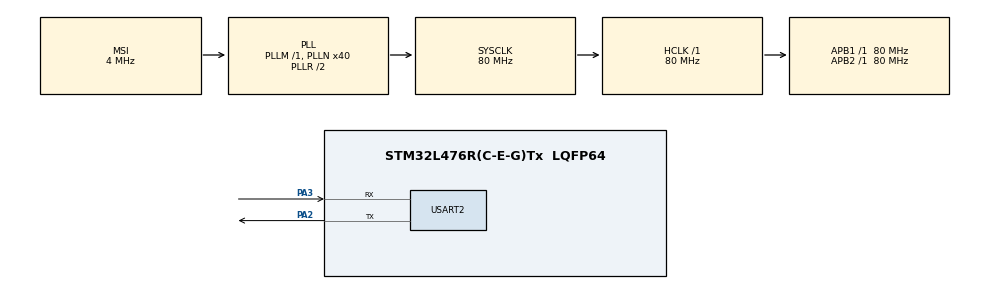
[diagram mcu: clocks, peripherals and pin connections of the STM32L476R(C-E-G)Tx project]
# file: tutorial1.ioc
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ADC1.Channel-5\#ChannelRegularConversion=ADC_CHANNEL_TEMPSENSOR
ADC1.NbrOfConversionFlag=1
ADC1.OffsetNumber-5\#ChannelRegularConversion=ADC_OFFSET_NONE
ADC1.Rank-5\#ChannelRegularConversion=1
ADC1.SamplingTime-5\#ChannelRegularConversion=ADC_SAMPLETIME_2CYCLES_5
ADC1.master=1
Mcu.Family=STM32L4
Mcu.Name=STM32L476R(C-E-G)Tx
Mcu.Package=LQFP64
NVIC.PriorityGroup=NVIC_PRIORITYGROUP_4
PA2.Mode=Asynchronous
PA2.Signal=USART2_TX
PA3.Mode=Asynchronous
PA3.Signal=USART2_RX
PH0-OSC_IN\ (PH0).Mode=HSE-External-Oscillator
PH0-OSC_IN\ (PH0).Signal=RCC_OSC_IN
PH1-OSC_OUT\ (PH1).Mode=HSE-External-Oscillator
PH1-OSC_OUT\ (PH1).Signal=RCC_OSC_OUT
ProjectManager.HeapSize=0x200
ProjectManager.StackSize=0x400
ProjectManager.TargetToolchain=MDK-ARM V5
RCC.ADCFreq_Value=48000000
RCC.AHBFreq_Value=80000000
RCC.APB1Freq_Value=80000000
RCC.APB1TimFreq_Value=80000000
RCC.APB2Freq_Value=80000000
RCC.APB2TimFreq_Value=80000000
RCC.CortexFreq_Value=80000000
RCC.HCLKFreq_Value=80000000
RCC.HSE_VALUE=8000000
RCC.HSI_VALUE=16000000
RCC.LSE_VALUE=32768
RCC.MSI_VALUE=4000000
RCC.PLLN=40
RCC.PLLSAI1N=24
RCC.SYSCLKFreq_VALUE=80000000
RCC.SYSCLKSource=RCC_SYSCLKSOURCE_PLLCLK
RCC.USBFreq_Value=48000000
RCC.VCOOutputFreq_Value=160000000
USART2.VirtualMode-Asynchronous=VM_ASYNC
VP_ADC1_TempSens_Input.Mode=IN-TempSens
board=custom

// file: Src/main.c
/* USER CODE BEGIN Header */
/**
  ******************************************************************************
  * @file           : main.c
  * @brief          : Main program body
  ******************************************************************************
  ** This notice applies to any and all portions of this file
  * that are not between comment pairs USER CODE BEGIN and
  * USER CODE END. Other portions of this file, whether
  * inserted by the user or by software development tools
  * are owned by their respective copyright owners.
  *
  * COPYRIGHT(c) 2019 STMicroelectronics
  *
  * Redistribution and use in source and binary forms, with or without modification,
  * are permitted provided that the following conditions are met:
  *   1. Redistributions of source code must retain the above copyright notice,
  *      this list of conditions and the following disclaimer.
  *   2. Redistributions in binary form must reproduce the above copyright notice,
  *      this list of conditions and the following disclaimer in the documentation
  *      and/or other materials provided with the distribution.
  *   3. Neither the name of STMicroelectronics nor the names of its contributors
  *      may be used to endorse or promote products derived from this software
  *      without specific prior written permission.
  *
  * THIS SOFTWARE IS PROVIDED BY THE COPYRIGHT HOLDERS AND CONTRIBUTORS "AS IS"
  * AND ANY EXPRESS OR IMPLIED WARRANTIES, INCLUDING, BUT NOT LIMITED TO, THE
  * IMPLIED WARRANTIES OF MERCHANTABILITY AND FITNESS FOR A PARTICULAR PURPOSE ARE
  * DISCLAIMED. IN NO EVENT SHALL THE COPYRIGHT HOLDER OR CONTRIBUTORS BE LIABLE
  * FOR ANY DIRECT, INDIRECT, INCIDENTAL, SPECIAL, EXEMPLARY, OR CONSEQUENTIAL
  * DAMAGES (INCLUDING, BUT NOT LIMITED TO, PROCUREMENT OF SUBSTITUTE GOODS OR
  * SERVICES; LOSS OF USE, DATA, OR PROFITS; OR BUSINESS INTERRUPTION) HOWEVER
  * CAUSED AND ON ANY THEORY OF LIABILITY, WHETHER IN CONTRACT, STRICT LIABILITY,
  * OR TORT (INCLUDING NEGLIGENCE OR OTHERWISE) ARISING IN ANY WAY OUT OF THE USE
  * OF THIS SOFTWARE, EVEN IF ADVISED OF THE POSSIBILITY OF SUCH DAMAGE.
  *
  ******************************************************************************
  */
/* USER CODE END Header */

#include "main.h"

ADC_HandleTypeDef hadc1;

UART_HandleTypeDef huart2;

void SystemClock_Config(void);
static void MX_GPIO_Init(void);
static void MX_ADC1_Init(void);
static void MX_USART2_UART_Init(void);

int main(void)
{

  /* MCU Configuration--------------------------------------------------------*/

  /* Reset of all peripherals, Initializes the Flash interface and the Systick. */
  HAL_Init();

  /* Configure the system clock */
  SystemClock_Config();

  /* Initialize all configured peripherals */
  MX_GPIO_Init();
  MX_ADC1_Init();
  MX_USART2_UART_Init();

  /* Infinite loop */
  /* USER CODE BEGIN WHILE */
	uint8_t dataIn[2]={'9','9'};
	uint8_t data[11]={'M','E','S','S','U','R','E',' ','I','S',' '};
	uint8_t tab[3]={' ',' ',' '};
	uint8_t messureADC=53;
	uint8_t messureADC2=53;
	uint8_t Vsense=53;
  while (1)
  {
    /* USER CODE END WHILE */

    /* USER CODE BEGIN 3 */
		HAL_ADC_Start(&hadc1);
		if(HAL_ADC_PollForConversion(&hadc1,2000)==HAL_OK){
		messureADC=HAL_ADC_GetValue(&hadc1);
		Vsense=(3*messureADC/4095);
		messureADC = ((Vsense-0.76)/0.0025)+25;
			dataIn[0]=(messureADC/10)+'0';
			dataIn[1]=(messureADC%10)+'0';

		}
		//HAL_UART_Receive(&huart1,data,11,1000);
		HAL_UART_Transmit(&huart2,data,11,1000);
		HAL_UART_Transmit(&huart2,dataIn,2,1000);
		HAL_UART_Transmit(&huart2,tab,3,1000);
		HAL_Delay(3000);
		//Debuggers is saying the temperature value is 23 i have to convert it to the ascii code

  }
  /* USER CODE END 3 */
}

void SystemClock_Config(void)
{
  RCC_OscInitTypeDef RCC_OscInitStruct = {0};
  RCC_ClkInitTypeDef RCC_ClkInitStruct = {0};
  RCC_PeriphCLKInitTypeDef PeriphClkInit = {0};

  /**Initializes the CPU, AHB and APB busses clocks
  */
  RCC_OscInitStruct.OscillatorType = RCC_OSCILLATORTYPE_MSI;
  RCC_OscInitStruct.MSIState = RCC_MSI_ON;
  RCC_OscInitStruct.MSICalibrationValue = 0;
  RCC_OscInitStruct.MSIClockRange = RCC_MSIRANGE_6;
  RCC_OscInitStruct.PLL.PLLState = RCC_PLL_ON;
  RCC_OscInitStruct.PLL.PLLSource = RCC_PLLSOURCE_MSI;
  RCC_OscInitStruct.PLL.PLLM = 1;
  RCC_OscInitStruct.PLL.PLLN = 40;
  RCC_OscInitStruct.PLL.PLLP = RCC_PLLP_DIV7;
  RCC_OscInitStruct.PLL.PLLQ = RCC_PLLQ_DIV2;
  RCC_OscInitStruct.PLL.PLLR = RCC_PLLR_DIV2;
  if (HAL_RCC_OscConfig(&RCC_OscInitStruct) != HAL_OK)
  {
    Error_Handler();
  }
  /**Initializes the CPU, AHB and APB busses clocks
  */
  RCC_ClkInitStruct.ClockType = RCC_CLOCKTYPE_HCLK|RCC_CLOCKTYPE_SYSCLK
                              |RCC_CLOCKTYPE_PCLK1|RCC_CLOCKTYPE_PCLK2;
  RCC_ClkInitStruct.SYSCLKSource = RCC_SYSCLKSOURCE_PLLCLK;
  RCC_ClkInitStruct.AHBCLKDivider = RCC_SYSCLK_DIV1;
  RCC_ClkInitStruct.APB1CLKDivider = RCC_HCLK_DIV1;
  RCC_ClkInitStruct.APB2CLKDivider = RCC_HCLK_DIV1;

  if (HAL_RCC_ClockConfig(&RCC_ClkInitStruct, FLASH_LATENCY_4) != HAL_OK)
  {
    Error_Handler();
  }
  PeriphClkInit.PeriphClockSelection = RCC_PERIPHCLK_USART2|RCC_PERIPHCLK_ADC;
  PeriphClkInit.Usart2ClockSelection = RCC_USART2CLKSOURCE_PCLK1;
  PeriphClkInit.AdcClockSelection = RCC_ADCCLKSOURCE_PLLSAI1;
  PeriphClkInit.PLLSAI1.PLLSAI1Source = RCC_PLLSOURCE_MSI;
  PeriphClkInit.PLLSAI1.PLLSAI1M = 1;
  PeriphClkInit.PLLSAI1.PLLSAI1N = 24;
  PeriphClkInit.PLLSAI1.PLLSAI1P = RCC_PLLP_DIV7;
  PeriphClkInit.PLLSAI1.PLLSAI1Q = RCC_PLLQ_DIV2;
  PeriphClkInit.PLLSAI1.PLLSAI1R = RCC_PLLR_DIV2;
  PeriphClkInit.PLLSAI1.PLLSAI1ClockOut = RCC_PLLSAI1_ADC1CLK;
  if (HAL_RCCEx_PeriphCLKConfig(&PeriphClkInit) != HAL_OK)
  {
    Error_Handler();
  }
  /**Configure the main internal regulator output voltage
  */
  if (HAL_PWREx_ControlVoltageScaling(PWR_REGULATOR_VOLTAGE_SCALE1) != HAL_OK)
  {
    Error_Handler();
  }
}

static void MX_ADC1_Init(void)
{

  ADC_MultiModeTypeDef multimode = {0};
  ADC_ChannelConfTypeDef sConfig = {0};

  /**Common config
  */
  hadc1.Instance = ADC1;
  hadc1.Init.ClockPrescaler = ADC_CLOCK_ASYNC_DIV1;
  hadc1.Init.Resolution = ADC_RESOLUTION_12B;
  hadc1.Init.DataAlign = ADC_DATAALIGN_RIGHT;
  hadc1.Init.ScanConvMode = ADC_SCAN_DISABLE;
  hadc1.Init.EOCSelection = ADC_EOC_SINGLE_CONV;
  hadc1.Init.LowPowerAutoWait = DISABLE;
  hadc1.Init.ContinuousConvMode = DISABLE;
  hadc1.Init.NbrOfConversion = 1;
  hadc1.Init.DiscontinuousConvMode = DISABLE;
  hadc1.Init.ExternalTrigConv = ADC_SOFTWARE_START;
  hadc1.Init.ExternalTrigConvEdge = ADC_EXTERNALTRIGCONVEDGE_NONE;
  hadc1.Init.DMAContinuousRequests = DISABLE;
  hadc1.Init.Overrun = ADC_OVR_DATA_PRESERVED;
  hadc1.Init.OversamplingMode = DISABLE;
  if (HAL_ADC_Init(&hadc1) != HAL_OK)
  {
    Error_Handler();
  }
  /**Configure the ADC multi-mode
  */
  multimode.Mode = ADC_MODE_INDEPENDENT;
  if (HAL_ADCEx_MultiModeConfigChannel(&hadc1, &multimode) != HAL_OK)
  {
    Error_Handler();
  }
  /**Configure Regular Channel
  */
  sConfig.Channel = ADC_CHANNEL_TEMPSENSOR;
  sConfig.Rank = ADC_REGULAR_RANK_1;
  sConfig.SamplingTime = ADC_SAMPLETIME_2CYCLES_5;
  sConfig.SingleDiff = ADC_SINGLE_ENDED;
  sConfig.OffsetNumber = ADC_OFFSET_NONE;
  sConfig.Offset = 0;
  if (HAL_ADC_ConfigChannel(&hadc1, &sConfig) != HAL_OK)
  {
    Error_Handler();
  }

}

static void MX_USART2_UART_Init(void)
{

  huart2.Instance = USART2;
  huart2.Init.BaudRate = 115200;
  huart2.Init.WordLength = UART_WORDLENGTH_8B;
  huart2.Init.StopBits = UART_STOPBITS_1;
  huart2.Init.Parity = UART_PARITY_NONE;
  huart2.Init.Mode = UART_MODE_TX_RX;
  huart2.Init.HwFlowCtl = UART_HWCONTROL_NONE;
  huart2.Init.OverSampling = UART_OVERSAMPLING_16;
  huart2.Init.OneBitSampling = UART_ONE_BIT_SAMPLE_DISABLE;
  huart2.AdvancedInit.AdvFeatureInit = UART_ADVFEATURE_NO_INIT;
  if (HAL_UART_Init(&huart2) != HAL_OK)
  {
    Error_Handler();
  }

}

static void MX_GPIO_Init(void)
{

  /* GPIO Ports Clock Enable */
  __HAL_RCC_GPIOH_CLK_ENABLE();
  __HAL_RCC_GPIOA_CLK_ENABLE();

}

void Error_Handler(void)
{
}

/************************ (C) COPYRIGHT STMicroelectronics *****END OF FILE****/
